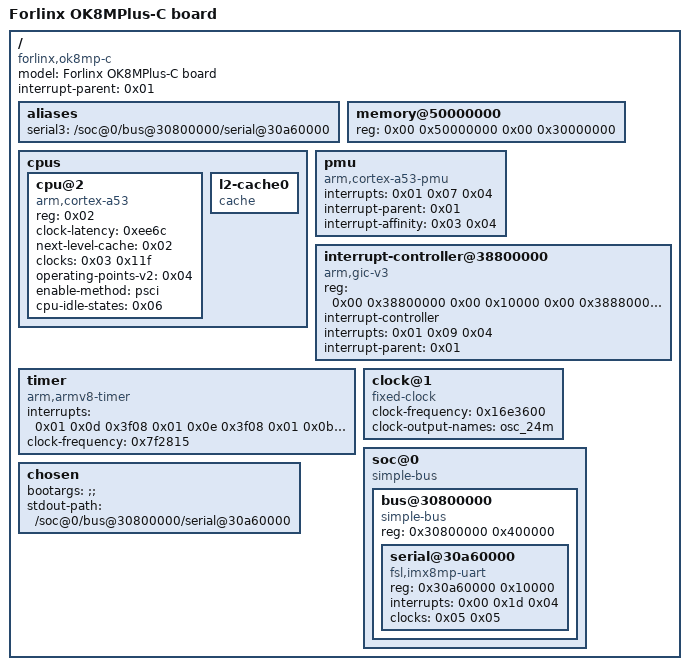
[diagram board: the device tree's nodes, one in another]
/dts-v1/;

/ {
	compatible = "forlinx,ok8mp-c\0fsl,imx8mp-evk\0fsl,imx8mp";
	model = "Forlinx OK8MPlus-C board";
	interrupt-parent = <0x01>;
	#address-cells = <0x02>;
	#size-cells = <0x02>;

	aliases {
		serial3 = "/soc@0/bus@30800000/serial@30a60000";
	};

	memory@50000000 {
		device_type = "memory";
		reg = <0x00 0x50000000 0x00 0x30000000>;
	};

	cpus {
		#address-cells = <0x01>;
		#size-cells = <0x00>;

		cpu@2 {
			device_type = "cpu";
			compatible = "arm,cortex-a53";
			reg = <0x02>;
			clock-latency = <0xee6c>;
			next-level-cache = <0x02>;
			clocks = <0x03 0x11f>;
			operating-points-v2 = <0x04>;
			enable-method = "psci";
			#cooling-cells = <0x02>;
			cpu-idle-states = <0x06>;
			phandle = <0x13>;
		};

		l2-cache0 {
			compatible = "cache";
			phandle = <0x02>;
		};
	};

	pmu {
		compatible = "arm,cortex-a53-pmu";
		interrupts = <0x01 0x07 0x04>;
		interrupt-parent = <0x01>;
		interrupt-affinity = <0x03 0x04>;
	};

	interrupt-controller@38800000 {
		compatible = "arm,gic-v3";
		reg = <0x00 0x38800000 0x00 0x10000 0x00 0x38880000 0x00 0xc0000>;
		#interrupt-cells = <0x03>;
		interrupt-controller;
		interrupts = <0x01 0x09 0x04>;
		interrupt-parent = <0x01>;
		phandle = <0x01>;
	};

	timer {
		compatible = "arm,armv8-timer";
		interrupts = <0x01 0x0d 0x3f08 0x01 0x0e 0x3f08 0x01 0x0b 0x3f08 0x01 0x0a 0x3f08>;
		clock-frequency = <0x7f2815>;
	};

	clock@1 {
		compatible = "fixed-clock";
		#clock-cells = <0x00>;
		clock-frequency = <0x16e3600>;
		clock-output-names = "osc_24m";
		phandle = <0x05>;
	};

	soc@0 {
		compatible = "simple-bus";
		#address-cells = <0x01>;
		#size-cells = <0x01>;
		ranges = <0x00 0x00 0x00 0x3e000000>;

		bus@30800000 {
			compatible = "simple-bus";
			#address-cells = <0x01>;
			#size-cells = <0x01>;
			reg = <0x30800000 0x400000>;
			ranges;

			serial@30a60000 {
				compatible = "fsl,imx8mp-uart\0fsl,imx6q-uart";
				reg = <0x30a60000 0x10000>;
				interrupts = <0x00 0x1d 0x04>;
				clocks = <0x05 0x05>;
				clock-names = "ipg\0per";
				status = "okay";
			};
		};
	};

	chosen {
		bootargs = ";;";
		stdout-path = "/soc@0/bus@30800000/serial@30a60000";
	};
};
